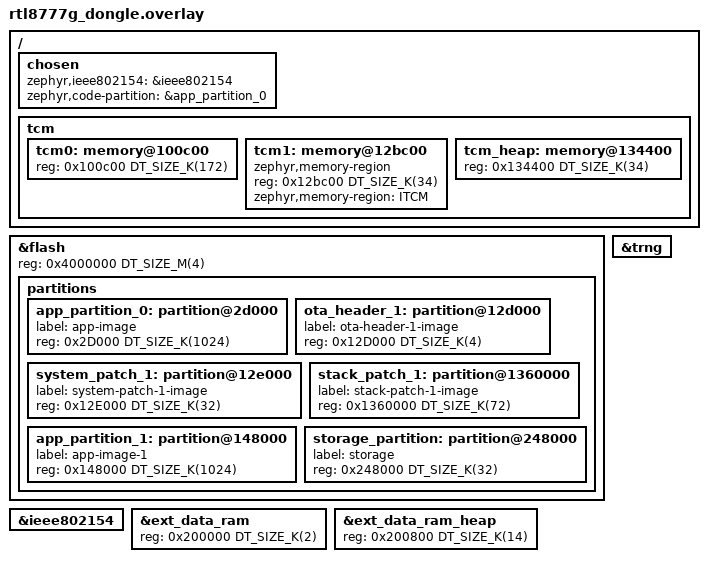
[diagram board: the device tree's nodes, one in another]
/ {
	chosen {
		zephyr,ieee802154 = &ieee802154;
		zephyr,code-partition = &app_partition_0;
	};

	tcm {
		/delete-node/ memory@100c00;
		/delete-node/ memory@119c00;
		/delete-node/ memory@133c00;

		tcm0: memory@100c00 {
			device_type = "tcm0, used as zephyr-sram";
			reg = <0x100c00 DT_SIZE_K(172)>;
		};
		tcm1: memory@12bc00 {
			device_type = "tcm1, used as zephyr-itcm";
			compatible = "zephyr,memory-region", "arm,itcm";
			reg = <0x12bc00 DT_SIZE_K(34)>;
			zephyr,memory-region = "ITCM";
		};
		tcm_heap: memory@134400 {
			device_type = "tcm heap region";
			reg = <0x134400 DT_SIZE_K(34)>;
		};
	};
};

&flash {
	reg = <0x4000000 DT_SIZE_M(4)>;
	partitions {
		/delete-node/ partition@2d000;
		/delete-node/ partition@94000;
		/delete-node/ partition@fc000;
		/delete-node/ partition@3fc000;

		app_partition_0: partition@2d000 {
			label = "app-image";
			reg = <0x2D000 DT_SIZE_K(1024)>;
		};
		/* Bank 1 */
		ota_header_1: partition@12d000 {
			label = "ota-header-1-image";
			reg = <0x12D000 DT_SIZE_K(4)>;
		};
		system_patch_1: partition@12e000 {
			label = "system-patch-1-image";
			reg = <0x12E000 DT_SIZE_K(32)>;
		};
		stack_patch_1: partition@1360000 {
			label = "stack-patch-1-image";
			reg = <0x1360000 DT_SIZE_K(72)>;
		};
		app_partition_1: partition@148000 {
			label = "app-image-1";
			reg = <0x148000 DT_SIZE_K(1024)>;
		};
		/* storage */
		storage_partition: partition@248000 {
			label = "storage";
			reg = <0x248000 DT_SIZE_K(32)>;
		};
	};
};

&trng {
	status = "okay";
};

&ieee802154 {
	status = "okay";
};

&ext_data_ram {
	reg = <0x200000 DT_SIZE_K(2)>;
};

&ext_data_ram_heap {
	reg = <0x200800 DT_SIZE_K(14)>;
};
